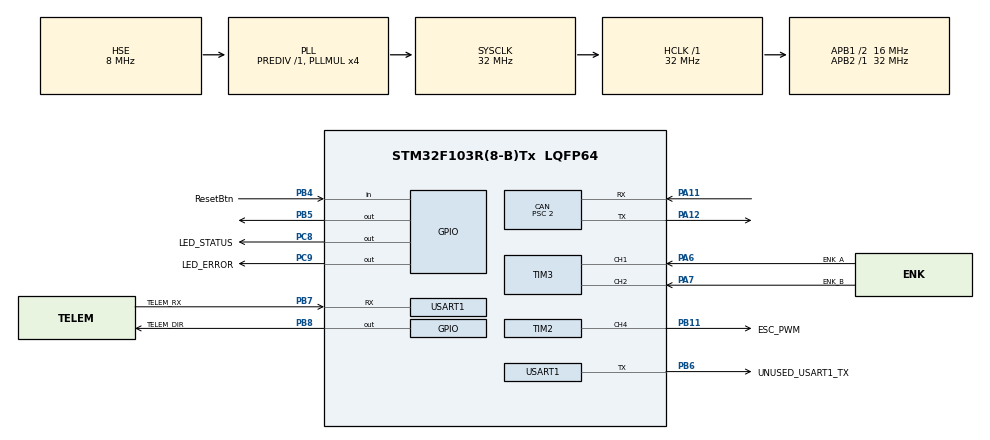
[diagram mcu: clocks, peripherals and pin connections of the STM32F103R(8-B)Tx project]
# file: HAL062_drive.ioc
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CAN.BS1=CAN_BS1_12TQ
CAN.BS2=CAN_BS2_3TQ
CAN.CalculateBaudRate=500000
CAN.CalculateTimeBit=2000
CAN.CalculateTimeQuantum=125.0
CAN.Prescaler=2
Dma.Request0=USART1_RX
Dma.USART1_RX.0.Direction=DMA_PERIPH_TO_MEMORY
Dma.USART1_RX.0.Instance=DMA1_Channel5
Dma.USART1_RX.0.MemDataAlignment=DMA_MDATAALIGN_BYTE
Dma.USART1_RX.0.MemInc=DMA_MINC_ENABLE
Dma.USART1_RX.0.Mode=DMA_CIRCULAR
Dma.USART1_RX.0.PeriphDataAlignment=DMA_PDATAALIGN_BYTE
Dma.USART1_RX.0.PeriphInc=DMA_PINC_DISABLE
Dma.USART1_RX.0.Priority=DMA_PRIORITY_LOW
Mcu.Family=STM32F1
Mcu.Name=STM32F103R(8-B)Tx
Mcu.Package=LQFP64
NVIC.CAN1_RX1_IRQn=true\:0\:0\:false\:false\:true\:true\:true\:true
NVIC.CAN1_SCE_IRQn=true\:0\:0\:false\:false\:true\:true\:true\:true
NVIC.DMA1_Channel5_IRQn=true\:0\:0\:false\:false\:true\:false\:true\:true
NVIC.PriorityGroup=NVIC_PRIORITYGROUP_4
NVIC.TIM4_IRQn=true\:0\:0\:false\:false\:true\:true\:true\:true
NVIC.USART1_IRQn=true\:0\:0\:false\:false\:true\:true\:true\:true
NVIC.USB_HP_CAN1_TX_IRQn=true\:0\:0\:false\:false\:true\:true\:true\:true
NVIC.USB_LP_CAN1_RX0_IRQn=true\:0\:0\:false\:false\:true\:true\:true\:true
PA11.Mode=CAN_Activate
PA11.Signal=CAN_RX
PA12.Mode=CAN_Activate
PA12.Signal=CAN_TX
PA13.Mode=Serial_Wire
PA13.Signal=SYS_JTMS-SWDIO
PA14.Mode=Serial_Wire
PA14.Signal=SYS_JTCK-SWCLK
PA6.GPIO_Label=ENK_A
PA6.Signal=S_TIM3_CH1
PA7.GPIO_Label=ENK_B
PA7.Signal=S_TIM3_CH2
PB11.GPIO_Label=ESC_PWM
PB11.Signal=S_TIM2_CH4
PB4.GPIO_Label=ResetBtn
PB4.Signal=GPIO_Input
PB5.Signal=GPIO_Output
PB6.GPIO_Label=UNUSED_USART1_TX
PB6.Mode=Asynchronous
PB6.Signal=USART1_TX
PB7.GPIO_Label=TELEM_RX
PB7.Mode=Asynchronous
PB7.Signal=USART1_RX
PB8.GPIO_Label=TELEM_DIR
PB8.Signal=GPIO_Output
PC8.GPIO_Label=LED_STATUS
PC8.Signal=GPIO_Output
PC9.GPIO_Label=LED_ERROR
PC9.Signal=GPIO_Output
PD0-OSC_IN.Mode=HSE-External-Oscillator
PD0-OSC_IN.Signal=RCC_OSC_IN
PD1-OSC_OUT.Mode=HSE-External-Oscillator
PD1-OSC_OUT.Signal=RCC_OSC_OUT
ProjectManager.HeapSize=0x200
ProjectManager.StackSize=0x400
ProjectManager.TargetToolchain=CMake
RCC.AHBFreq_Value=32000000
RCC.APB1CLKDivider=RCC_HCLK_DIV2
RCC.APB1Freq_Value=16000000
RCC.APB1TimFreq_Value=32000000
RCC.APB2Freq_Value=32000000
RCC.APB2TimFreq_Value=32000000
RCC.HCLKFreq_Value=32000000
RCC.PLLMUL=RCC_PLL_MUL4
RCC.PLLSourceVirtual=RCC_PLLSOURCE_HSE
RCC.SYSCLKFreq_VALUE=32000000
RCC.SYSCLKSource=RCC_SYSCLKSOURCE_PLLCLK
RCC.USBFreq_Value=32000000
SH.S_TIM2_CH4.0=TIM2_CH4,PWM Generation4 CH4
SH.S_TIM3_CH1.0=TIM3_CH1,Encoder_Interface
SH.S_TIM3_CH2.0=TIM3_CH2,Encoder_Interface
TIM1.Period=59999
TIM1.Prescaler=11
TIM2.Channel-PWM\ Generation4\ CH4=TIM_CHANNEL_4
TIM2.Period=63999
TIM2.Prescaler=9
TIM3.EncoderMode=TIM_ENCODERMODE_TI12
TIM3.IC1Filter=15
TIM3.IC2Filter=15
TIM4.Period=39999
TIM4.Prescaler=7
USART1.Mode=MODE_RX
USART1.VirtualMode=VM_ASYNC
VP_TIM1_VS_ClockSourceINT.Mode=Internal
VP_TIM4_VS_ClockSourceINT.Mode=Internal
board=custom

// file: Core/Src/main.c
/* USER CODE BEGIN Header */
/**
 ******************************************************************************
 * @file           : main.c
 * @brief          : Main program body
 ******************************************************************************
 * @attention
 *
 * Copyright (c) 2026 STMicroelectronics.
 * All rights reserved.
 *
 * This software is licensed under terms that can be found in the LICENSE file
 * in the root directory of this software component.
 * If no LICENSE file comes with this software, it is provided AS-IS.
 *
 ******************************************************************************
 */
/* USER CODE END Header */
#include "main.h"
#include "board_params.h"
#include "can.h"
#include "dma.h"
#include "gpio.h"
#include "tim.h"
#include "usart.h"

/* USER CODE BEGIN Includes */
#include "telemetry.h"
/* USER CODE END Includes */

/* USER CODE BEGIN PV */
volatile uint16_t last_encoder_cnt = 0;
volatile int16_t current_speed = 0;
volatile int16_t target_speed = 0;
volatile float error = 0;
pid_reg PID;
/* USER CODE END PV */

void SystemClock_Config(void);

int main(void) {

    /* MCU Configuration--------------------------------------------------------*/

    /* Reset of all peripherals, Initializes the Flash interface and the Systick. */
    HAL_Init();

    /* Configure the system clock */
    SystemClock_Config();

    /* Initialize all configured peripherals */
    MX_GPIO_Init();
    MX_DMA_Init();
    MX_CAN_Init();
    MX_TIM1_Init();
    MX_TIM4_Init();
    MX_TIM2_Init();
    MX_TIM3_Init();
    MX_USART1_UART_Init();
    /* USER CODE BEGIN 2 */
    HAL_TIM_Encoder_Start(&htim3, TIM_CHANNEL_ALL);
    HAL_TIM_Base_Start_IT(&htim4);
    HAL_TIM_PWM_Start(&htim2, TIM_CHANNEL_4);
    pid_init(&PID, 1600, -1600, 4.0, 15.0, 0);
    HAL_GPIO_WritePin(GPIOB, GPIO_PIN_5, GPIO_PIN_SET);

    if (ENABLE_TELEMETRY)
        telemetry_init(&huart1);
    /* USER CODE END 2 */

    /* Infinite loop */
    while (1) {

    }
}

void SystemClock_Config(void) {
    RCC_OscInitTypeDef RCC_OscInitStruct = {0};
    RCC_ClkInitTypeDef RCC_ClkInitStruct = {0};

    /** Initializes the RCC Oscillators according to the specified parameters
     * in the RCC_OscInitTypeDef structure.
     */
    RCC_OscInitStruct.OscillatorType = RCC_OSCILLATORTYPE_HSE;
    RCC_OscInitStruct.HSEState = RCC_HSE_ON;
    RCC_OscInitStruct.HSEPredivValue = RCC_HSE_PREDIV_DIV1;
    RCC_OscInitStruct.HSIState = RCC_HSI_ON;
    RCC_OscInitStruct.PLL.PLLState = RCC_PLL_ON;
    RCC_OscInitStruct.PLL.PLLSource = RCC_PLLSOURCE_HSE;
    RCC_OscInitStruct.PLL.PLLMUL = RCC_PLL_MUL4;
    if (HAL_RCC_OscConfig(&RCC_OscInitStruct) != HAL_OK) {
        Error_Handler();
    }

    /** Initializes the CPU, AHB and APB buses clocks
     */
    RCC_ClkInitStruct.ClockType =
        RCC_CLOCKTYPE_HCLK | RCC_CLOCKTYPE_SYSCLK | RCC_CLOCKTYPE_PCLK1 | RCC_CLOCKTYPE_PCLK2;
    RCC_ClkInitStruct.SYSCLKSource = RCC_SYSCLKSOURCE_PLLCLK;
    RCC_ClkInitStruct.AHBCLKDivider = RCC_SYSCLK_DIV1;
    RCC_ClkInitStruct.APB1CLKDivider = RCC_HCLK_DIV2;
    RCC_ClkInitStruct.APB2CLKDivider = RCC_HCLK_DIV1;

    if (HAL_RCC_ClockConfig(&RCC_ClkInitStruct, FLASH_LATENCY_1) != HAL_OK) {
        Error_Handler();
    }
}

void Error_Handler(void) {
    __disable_irq();
    while (1) {
    }
}
